# dsPIC33FJ64GS606 register map
Vendor: Microchip; Series: dsPIC33FJ64GS; File version: 1.4.228
Registers are 16-bit, read-write, no defined reset value unless marked. A register's access mark holds for its fields unless they carry their own. Offsets are from the block's base; [hi:lo] are bit positions; {n}, {i} and the like mark numbered series.

## PWM_MASTER — PWM_MASTER peripheral registers
Base 0x00000400
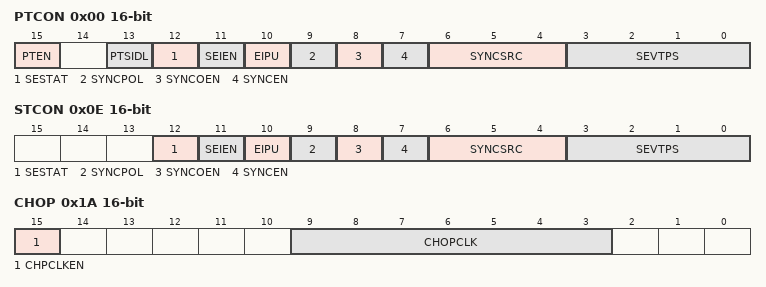
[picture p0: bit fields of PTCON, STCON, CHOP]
0x00 PTCON
  [15] PTEN — PTCON field PTEN
  [13] PTSIDL — PTCON field PTSIDL
  [12] SESTAT — PTCON field SESTAT
  [11] SEIEN — PTCON field SEIEN
  [10] EIPU — PTCON field EIPU
  [9] SYNCPOL — PTCON field SYNCPOL
  [8] SYNCOEN — PTCON field SYNCOEN
  [7] SYNCEN — PTCON field SYNCEN
  [6:4] SYNCSRC — PTCON field SYNCSRC
  [3:0] SEVTPS — PTCON field SEVTPS
0x02 PTCON2
  [2:0] PCLKDIV — PTCON2 field PCLKDIV
0x04 PTPER
  [15:0] PTPER — PTPER register value
0x06 SEVTCMP
  [15:0] SEVTCMP — SEVTCMP register value
0x0A MDC
  [15:0] MDC — MDC register value
0x0E STCON
  [12] SESTAT — STCON field SESTAT
  [11] SEIEN — STCON field SEIEN
  [10] EIPU — STCON field EIPU
  [9] SYNCPOL — STCON field SYNCPOL
  [8] SYNCOEN — STCON field SYNCOEN
  [7] SYNCEN — STCON field SYNCEN
  [6:4] SYNCSRC — STCON field SYNCSRC
  [3:0] SEVTPS — STCON field SEVTPS
0x10 STCON2
  [2:0] PCLKDIV — STCON2 field PCLKDIV
0x12 STPER
  [15:0] STPER — STPER register value
0x14 SSEVTCMP
  [15:0] SSEVTCMP — SSEVTCMP register value
0x1A CHOP
  [15] CHPCLKEN — CHOP field CHPCLKEN
  [9:3] CHOPCLK — CHOP field CHOPCLK

## PWM1 — PWM1 peripheral registers
Base 0x00000420
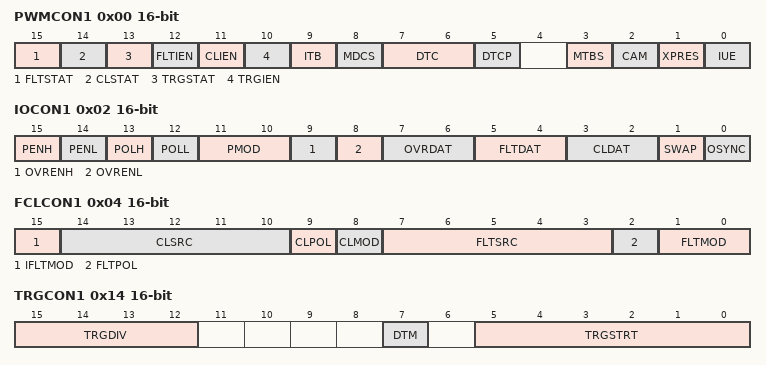
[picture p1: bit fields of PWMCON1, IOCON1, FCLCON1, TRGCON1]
0x00 PWMCON1
  [15] FLTSTAT — PWMCON1 field FLTSTAT
  [14] CLSTAT — PWMCON1 field CLSTAT
  [13] TRGSTAT — PWMCON1 field TRGSTAT
  [12] FLTIEN — PWMCON1 field FLTIEN
  [11] CLIEN — PWMCON1 field CLIEN
  [10] TRGIEN — PWMCON1 field TRGIEN
  [9] ITB — PWMCON1 field ITB
  [8] MDCS — PWMCON1 field MDCS
  [7:6] DTC — PWMCON1 field DTC
  [5] DTCP — PWMCON1 field DTCP
  [3] MTBS — PWMCON1 field MTBS
  [2] CAM — PWMCON1 field CAM
  [1] XPRES — PWMCON1 field XPRES
  [0] IUE — PWMCON1 field IUE
0x02 IOCON1
  [15] PENH — IOCON1 field PENH
  [14] PENL — IOCON1 field PENL
  [13] POLH — IOCON1 field POLH
  [12] POLL — IOCON1 field POLL
  [11:10] PMOD — IOCON1 field PMOD
  [9] OVRENH — IOCON1 field OVRENH
  [8] OVRENL — IOCON1 field OVRENL
  [7:6] OVRDAT — IOCON1 field OVRDAT
  [5:4] FLTDAT — IOCON1 field FLTDAT
  [3:2] CLDAT — IOCON1 field CLDAT
  [1] SWAP — IOCON1 field SWAP
  [0] OSYNC — IOCON1 field OSYNC
0x04 FCLCON1
  [15] IFLTMOD — FCLCON1 field IFLTMOD
  [14:10] CLSRC — FCLCON1 field CLSRC
  [9] CLPOL — FCLCON1 field CLPOL
  [8] CLMOD — FCLCON1 field CLMOD
  [7:3] FLTSRC — FCLCON1 field FLTSRC
  [2] FLTPOL — FCLCON1 field FLTPOL
  [1:0] FLTMOD — FCLCON1 field FLTMOD
0x06 PDC1
  [15:0] PDC1 — PDC1 register value
0x08 PHASE1
  [15:0] PHASE1 — PHASE1 register value
0x0A DTR1
  [13:0] DTR — DTR1 dead-time value
0x0C ALTDTR1
  [13:0] ALTDTR — ALTDTR1 dead-time value
0x0E SDC1
  [15:0] SDC1 — SDC1 register value
0x10 SPHASE1
  [15:0] SPHASE1 — SPHASE1 register value
0x12 TRIG1
  [15:3] TRGCMP — TRIG1 field TRGCMP
0x14 TRGCON1
  [15:12] TRGDIV — TRGCON1 field TRGDIV
  [7] DTM — TRGCON1 field DTM
  [5:0] TRGSTRT — TRGCON1 field TRGSTRT
0x16 STRIG1
  [15:3] STRGCMP — STRIG1 field STRGCMP
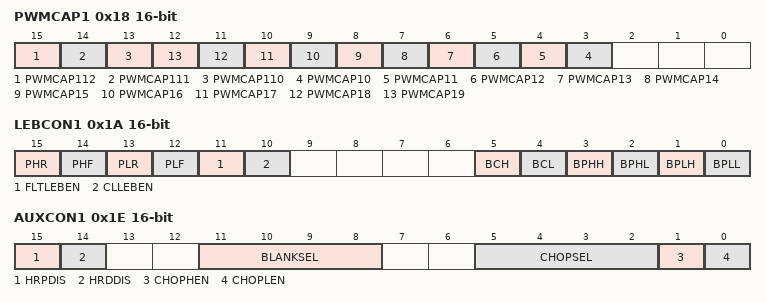
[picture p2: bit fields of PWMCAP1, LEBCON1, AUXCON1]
0x18 PWMCAP1
  [15] PWMCAP112 — PWMCAP1 field PWMCAP112
  [14] PWMCAP111 — PWMCAP1 field PWMCAP111
  [13] PWMCAP110 — PWMCAP1 field PWMCAP110
  [n-7] PWMCAP{n} (n=10..19) — PWMCAP1 field PWMCAP{n}
0x1A LEBCON1
  [15] PHR — LEBCON1 field PHR
  [14] PHF — LEBCON1 field PHF
  [13] PLR — LEBCON1 field PLR
  [12] PLF — LEBCON1 field PLF
  [11] FLTLEBEN — LEBCON1 field FLTLEBEN
  [10] CLLEBEN — LEBCON1 field CLLEBEN
  [5] BCH — LEBCON1 field BCH
  [4] BCL — LEBCON1 field BCL
  [3] BPHH — LEBCON1 field BPHH
  [2] BPHL — LEBCON1 field BPHL
  [1] BPLH — LEBCON1 field BPLH
  [0] BPLL — LEBCON1 field BPLL
0x1C LEBDLY1
  [11:3] LEB — LEBDLY1 field LEB
0x1E AUXCON1
  [15] HRPDIS — AUXCON1 field HRPDIS
  [14] HRDDIS — AUXCON1 field HRDDIS
  [11:8] BLANKSEL — AUXCON1 field BLANKSEL
  [5:2] CHOPSEL — AUXCON1 field CHOPSEL
  [1] CHOPHEN — AUXCON1 field CHOPHEN
  [0] CHOPLEN — AUXCON1 field CHOPLEN
